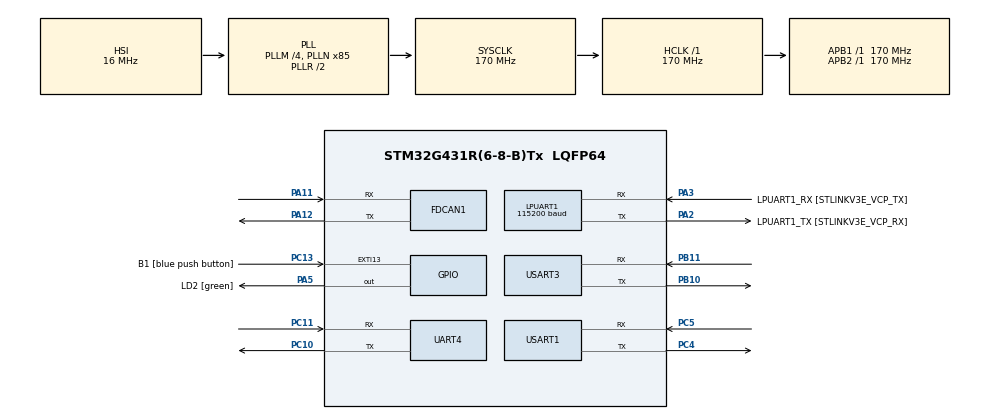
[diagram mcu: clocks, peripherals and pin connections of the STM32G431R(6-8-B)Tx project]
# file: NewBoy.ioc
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Dma.LPUART1_RX.0.Direction=DMA_PERIPH_TO_MEMORY
Dma.LPUART1_RX.0.EventEnable=DISABLE
Dma.LPUART1_RX.0.Instance=DMA1_Channel1
Dma.LPUART1_RX.0.MemDataAlignment=DMA_MDATAALIGN_BYTE
Dma.LPUART1_RX.0.MemInc=DMA_MINC_ENABLE
Dma.LPUART1_RX.0.Mode=DMA_NORMAL
Dma.LPUART1_RX.0.PeriphDataAlignment=DMA_PDATAALIGN_BYTE
Dma.LPUART1_RX.0.PeriphInc=DMA_PINC_DISABLE
Dma.LPUART1_RX.0.Polarity=HAL_DMAMUX_REQ_GEN_RISING
Dma.LPUART1_RX.0.Priority=DMA_PRIORITY_LOW
Dma.LPUART1_RX.0.RequestNumber=1
Dma.LPUART1_RX.0.SignalID=NONE
Dma.LPUART1_RX.0.SyncEnable=DISABLE
Dma.LPUART1_RX.0.SyncPolarity=HAL_DMAMUX_SYNC_NO_EVENT
Dma.LPUART1_RX.0.SyncRequestNumber=1
Dma.LPUART1_RX.0.SyncSignalID=NONE
Dma.Request0=LPUART1_RX
Dma.Request1=USART1_RX
Dma.Request2=USART3_RX
Dma.Request3=UART4_RX
Dma.UART4_RX.3.Direction=DMA_PERIPH_TO_MEMORY
Dma.UART4_RX.3.EventEnable=DISABLE
Dma.UART4_RX.3.Instance=DMA1_Channel4
Dma.UART4_RX.3.MemDataAlignment=DMA_MDATAALIGN_BYTE
Dma.UART4_RX.3.MemInc=DMA_MINC_ENABLE
Dma.UART4_RX.3.Mode=DMA_NORMAL
Dma.UART4_RX.3.PeriphDataAlignment=DMA_PDATAALIGN_BYTE
Dma.UART4_RX.3.PeriphInc=DMA_PINC_DISABLE
Dma.UART4_RX.3.Polarity=HAL_DMAMUX_REQ_GEN_RISING
Dma.UART4_RX.3.Priority=DMA_PRIORITY_LOW
Dma.UART4_RX.3.RequestNumber=1
Dma.UART4_RX.3.SignalID=NONE
Dma.UART4_RX.3.SyncEnable=DISABLE
Dma.UART4_RX.3.SyncPolarity=HAL_DMAMUX_SYNC_NO_EVENT
Dma.UART4_RX.3.SyncRequestNumber=1
Dma.UART4_RX.3.SyncSignalID=NONE
Dma.USART1_RX.1.Direction=DMA_PERIPH_TO_MEMORY
Dma.USART1_RX.1.EventEnable=DISABLE
Dma.USART1_RX.1.Instance=DMA1_Channel2
Dma.USART1_RX.1.MemDataAlignment=DMA_MDATAALIGN_BYTE
Dma.USART1_RX.1.MemInc=DMA_MINC_ENABLE
Dma.USART1_RX.1.Mode=DMA_NORMAL
Dma.USART1_RX.1.PeriphDataAlignment=DMA_PDATAALIGN_BYTE
Dma.USART1_RX.1.PeriphInc=DMA_PINC_DISABLE
Dma.USART1_RX.1.Polarity=HAL_DMAMUX_REQ_GEN_RISING
Dma.USART1_RX.1.Priority=DMA_PRIORITY_LOW
Dma.USART1_RX.1.RequestNumber=1
Dma.USART1_RX.1.SignalID=NONE
Dma.USART1_RX.1.SyncEnable=DISABLE
Dma.USART1_RX.1.SyncPolarity=HAL_DMAMUX_SYNC_NO_EVENT
Dma.USART1_RX.1.SyncRequestNumber=1
Dma.USART1_RX.1.SyncSignalID=NONE
Dma.USART3_RX.2.Direction=DMA_PERIPH_TO_MEMORY
Dma.USART3_RX.2.EventEnable=DISABLE
Dma.USART3_RX.2.Instance=DMA1_Channel3
Dma.USART3_RX.2.MemDataAlignment=DMA_MDATAALIGN_BYTE
Dma.USART3_RX.2.MemInc=DMA_MINC_ENABLE
Dma.USART3_RX.2.Mode=DMA_NORMAL
Dma.USART3_RX.2.PeriphDataAlignment=DMA_PDATAALIGN_BYTE
Dma.USART3_RX.2.PeriphInc=DMA_PINC_DISABLE
Dma.USART3_RX.2.Polarity=HAL_DMAMUX_REQ_GEN_RISING
Dma.USART3_RX.2.Priority=DMA_PRIORITY_LOW
Dma.USART3_RX.2.RequestNumber=1
Dma.USART3_RX.2.SignalID=NONE
Dma.USART3_RX.2.SyncEnable=DISABLE
Dma.USART3_RX.2.SyncPolarity=HAL_DMAMUX_SYNC_NO_EVENT
Dma.USART3_RX.2.SyncRequestNumber=1
Dma.USART3_RX.2.SyncSignalID=NONE
FREERTOS.Tasks01=defaultTask,24,128,StartDefaultTask,Default,NULL,Dynamic,NULL,NULL
LPUART1.BaudRate=115200
Mcu.Family=STM32G4
Mcu.Name=STM32G431R(6-8-B)Tx
Mcu.Package=LQFP64
NVIC.DMA1_Channel1_IRQn=true\:0\:0\:false\:false\:true\:true\:false\:true
NVIC.DMA1_Channel2_IRQn=true\:0\:0\:false\:false\:true\:true\:false\:true
NVIC.DMA1_Channel3_IRQn=true\:0\:0\:false\:false\:true\:true\:false\:true
NVIC.DMA1_Channel4_IRQn=true\:0\:0\:false\:false\:true\:true\:false\:true
NVIC.LPUART1_IRQn=true\:0\:0\:false\:false\:true\:true\:true\:true
NVIC.PriorityGroup=NVIC_PRIORITYGROUP_4
NVIC.TIM1_UP_TIM16_IRQn=true\:0\:0\:false\:false\:true\:false\:false\:true
NVIC.TimeBase=TIM1_UP_TIM16_IRQn
NVIC.TimeBaseIP=TIM1
NVIC.UART4_IRQn=true\:0\:0\:false\:false\:true\:true\:true\:true
NVIC.USART1_IRQn=true\:0\:0\:false\:false\:true\:true\:true\:true
NVIC.USART3_IRQn=true\:0\:0\:false\:false\:true\:true\:true\:true
PA11.Mode=FDCANMaster
PA11.Signal=FDCAN1_RX
PA12.Mode=FDCANMaster
PA12.Signal=FDCAN1_TX
PA13.GPIO_Label=T_SWDIO
PA13.Mode=Serial_Wire
PA13.Signal=SYS_JTMS-SWDIO
PA14.GPIO_Label=T_SWCLK
PA14.Mode=Serial_Wire
PA14.Signal=SYS_JTCK-SWCLK
PA2.GPIO_Label=LPUART1_TX [STLINKV3E_VCP_RX]
PA2.Mode=Asynchronous
PA2.Signal=LPUART1_TX
PA3.GPIO_Label=LPUART1_RX [STLINKV3E_VCP_TX]
PA3.GPIO_PuPd=GPIO_PULLUP
PA3.Mode=Asynchronous
PA3.Signal=LPUART1_RX
PA5.GPIO_Label=LD2 [green]
PA5.Signal=GPIO_Output
PB10.Mode=Asynchronous
PB10.Signal=USART3_TX
PB11.GPIO_PuPd=GPIO_PULLUP
PB11.Mode=Asynchronous
PB11.Signal=USART3_RX
PB3.GPIO_Label=T_SWO
PB3.Signal=SYS_JTDO-SWO
PC10.Mode=Asynchronous
PC10.Signal=UART4_TX
PC11.GPIO_PuPd=GPIO_PULLUP
PC11.Mode=Asynchronous
PC11.Signal=UART4_RX
PC13.GPIO_Label=B1 [blue push button]
PC13.Signal=GPXTI13
PC14-OSC32_IN.Mode=LSE-External-Oscillator
PC14-OSC32_IN.Signal=RCC_OSC32_IN
PC15-OSC32_OUT.Mode=LSE-External-Oscillator
PC15-OSC32_OUT.Signal=RCC_OSC32_OUT
PC4.Mode=Asynchronous
PC4.Signal=USART1_TX
PC5.GPIO_PuPd=GPIO_PULLUP
PC5.Mode=Asynchronous
PC5.Signal=USART1_RX
PF0-OSC_IN.Mode=HSE-External-Oscillator
PF0-OSC_IN.Signal=RCC_OSC_IN
PF1-OSC_OUT.Mode=HSE-External-Oscillator
PF1-OSC_OUT.Signal=RCC_OSC_OUT
ProjectManager.HeapSize=0x200
ProjectManager.StackSize=0x400
ProjectManager.TargetToolchain=STM32CubeIDE
RCC.ADC12Freq_Value=170000000
RCC.AHBFreq_Value=170000000
RCC.APB1Freq_Value=170000000
RCC.APB1TimFreq_Value=170000000
RCC.APB2Freq_Value=170000000
RCC.APB2TimFreq_Value=170000000
RCC.CortexFreq_Value=170000000
RCC.EXTERNAL_CLOCK_VALUE=12288000
RCC.HCLKFreq_Value=170000000
RCC.HSE_VALUE=24000000
RCC.HSI48_VALUE=48000000
RCC.HSI_VALUE=16000000
RCC.PLLM=RCC_PLLM_DIV4
RCC.PLLN=85
RCC.RTCClockSelection=RCC_RTCCLKSOURCE_LSE
RCC.SYSCLKFreq_VALUE=170000000
RCC.SYSCLKSource=RCC_SYSCLKSOURCE_PLLCLK
RCC.USBFreq_Value=170000000
RCC.VCOOutputFreq_Value=340000000
USART1.VirtualMode-Asynchronous=VM_ASYNC
USART3.VirtualMode-Asynchronous=VM_ASYNC
VP_FREERTOS_VS_CMSIS_V2.Mode=CMSIS_V2
VP_SYS_VS_DBSignals.Mode=DisableDeadBatterySignals
VP_SYS_VS_tim1.Mode=TIM1
board=NUCLEO-G431RB

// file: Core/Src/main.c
/* USER CODE BEGIN Header */
/**
  ******************************************************************************
  * @file           : main.c
  * @brief          : Main program body
  ******************************************************************************
  * @attention
  *
  * <h2><center>&copy; Copyright (c) 2020 STMicroelectronics.
  * All rights reserved.</center></h2>
  *
  * This software component is licensed by ST under BSD 3-Clause license,
  * the "License"; You may not use this file except in compliance with the
  * License. You may obtain a copy of the License at:
  *                        opensource.org/licenses/BSD-3-Clause
  *
  ******************************************************************************
  */
/* USER CODE END Header */
#include "main.h"
#include "cmsis_os.h"
#include "dma.h"
#include "fdcan.h"
#include "usart.h"
#include "gpio.h"

void SystemClock_Config(void);
void MX_FREERTOS_Init(void);
/* USER CODE BEGIN PFP */
void netmodule_thread(void *argument);
/* USER CODE END PFP */

int main(void)
{

  /* MCU Configuration--------------------------------------------------------*/

  /* Reset of all peripherals, Initializes the Flash interface and the Systick. */
  HAL_Init();

  /* Configure the system clock */
  SystemClock_Config();

  /* Initialize all configured peripherals */
  MX_GPIO_Init();
  MX_DMA_Init();
  MX_LPUART1_UART_Init();
  MX_FDCAN1_Init();
  MX_UART4_Init();
  MX_USART1_UART_Init();
  MX_USART3_UART_Init();

  /* Init scheduler */
  osKernelInitialize();  /* Call init function for freertos objects (in freertos.c) */
  MX_FREERTOS_Init();
  /* Start scheduler */
  osKernelStart();

  /* We should never get here as control is now taken by the scheduler */
  /* Infinite loop */
  while (1)
  {

  }
}

void SystemClock_Config(void)
{
  RCC_OscInitTypeDef RCC_OscInitStruct = {0};
  RCC_ClkInitTypeDef RCC_ClkInitStruct = {0};
  RCC_PeriphCLKInitTypeDef PeriphClkInit = {0};

  /** Configure the main internal regulator output voltage
  */
  HAL_PWREx_ControlVoltageScaling(PWR_REGULATOR_VOLTAGE_SCALE1_BOOST);
  /** Initializes the RCC Oscillators according to the specified parameters
  * in the RCC_OscInitTypeDef structure.
  */
  RCC_OscInitStruct.OscillatorType = RCC_OSCILLATORTYPE_HSI;
  RCC_OscInitStruct.HSIState = RCC_HSI_ON;
  RCC_OscInitStruct.HSICalibrationValue = RCC_HSICALIBRATION_DEFAULT;
  RCC_OscInitStruct.PLL.PLLState = RCC_PLL_ON;
  RCC_OscInitStruct.PLL.PLLSource = RCC_PLLSOURCE_HSI;
  RCC_OscInitStruct.PLL.PLLM = RCC_PLLM_DIV4;
  RCC_OscInitStruct.PLL.PLLN = 85;
  RCC_OscInitStruct.PLL.PLLP = RCC_PLLP_DIV2;
  RCC_OscInitStruct.PLL.PLLQ = RCC_PLLQ_DIV2;
  RCC_OscInitStruct.PLL.PLLR = RCC_PLLR_DIV2;
  if (HAL_RCC_OscConfig(&RCC_OscInitStruct) != HAL_OK)
  {
    Error_Handler();
  }
  /** Initializes the CPU, AHB and APB buses clocks
  */
  RCC_ClkInitStruct.ClockType = RCC_CLOCKTYPE_HCLK|RCC_CLOCKTYPE_SYSCLK
                              |RCC_CLOCKTYPE_PCLK1|RCC_CLOCKTYPE_PCLK2;
  RCC_ClkInitStruct.SYSCLKSource = RCC_SYSCLKSOURCE_PLLCLK;
  RCC_ClkInitStruct.AHBCLKDivider = RCC_SYSCLK_DIV1;
  RCC_ClkInitStruct.APB1CLKDivider = RCC_HCLK_DIV1;
  RCC_ClkInitStruct.APB2CLKDivider = RCC_HCLK_DIV1;

  if (HAL_RCC_ClockConfig(&RCC_ClkInitStruct, FLASH_LATENCY_4) != HAL_OK)
  {
    Error_Handler();
  }
  /** Initializes the peripherals clocks
  */
  PeriphClkInit.PeriphClockSelection = RCC_PERIPHCLK_USART1|RCC_PERIPHCLK_USART3
                              |RCC_PERIPHCLK_UART4|RCC_PERIPHCLK_LPUART1
                              |RCC_PERIPHCLK_FDCAN;
  PeriphClkInit.Usart1ClockSelection = RCC_USART1CLKSOURCE_PCLK2;
  PeriphClkInit.Usart3ClockSelection = RCC_USART3CLKSOURCE_PCLK1;
  PeriphClkInit.Uart4ClockSelection = RCC_UART4CLKSOURCE_PCLK1;
  PeriphClkInit.Lpuart1ClockSelection = RCC_LPUART1CLKSOURCE_PCLK1;
  PeriphClkInit.FdcanClockSelection = RCC_FDCANCLKSOURCE_PCLK1;
  if (HAL_RCCEx_PeriphCLKConfig(&PeriphClkInit) != HAL_OK)
  {
    Error_Handler();
  }
}

/* USER CODE BEGIN 4 */
void netmodule_thread(void *argument)
{
}
/* USER CODE END 4 */

void HAL_TIM_PeriodElapsedCallback(TIM_HandleTypeDef *htim)
{
  if (htim->Instance == TIM1) {
    HAL_IncTick();
  }
}

void Error_Handler(void)
{
}

/************************ (C) COPYRIGHT STMicroelectronics *****END OF FILE****/

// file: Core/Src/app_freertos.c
/* USER CODE BEGIN Header */
/**
  ******************************************************************************
  * File Name          : app_freertos.c
  * Description        : Code for freertos applications
  ******************************************************************************
  * @attention
  *
  * <h2><center>&copy; Copyright (c) 2020 STMicroelectronics.
  * All rights reserved.</center></h2>
  *
  * This software component is licensed by ST under Ultimate Liberty license
  * SLA0044, the "License"; You may not use this file except in compliance with
  * the License. You may obtain a copy of the License at:
  *                             www.st.com/SLA0044
  *
  ******************************************************************************
  */
/* USER CODE END Header */

#include "FreeRTOS.h"
#include "task.h"
#include "main.h"
#include "cmsis_os.h"

/* USER CODE BEGIN Includes */
#include "usart.h"
/* USER CODE END Includes */

/* Definitions for defaultTask */
osThreadId_t defaultTaskHandle;
const osThreadAttr_t defaultTask_attributes = {
  .name = "defaultTask",
  .priority = (osPriority_t) osPriorityNormal,
  .stack_size = 128 * 4
};

void StartDefaultTask(void *argument);

void MX_FREERTOS_Init(void); /* (MISRA C 2004 rule 8.1) */

void MX_FREERTOS_Init(void) {

  /* Create the thread(s) */
  /* creation of defaultTask */
  defaultTaskHandle = osThreadNew(StartDefaultTask, NULL, &defaultTask_attributes);

}

void StartDefaultTask(void *argument)
{
  /* USER CODE BEGIN StartDefaultTask */
  /* Infinite loop */
  while (1)
  {
	HAL_Delay(1000);
	printf("haha\r\n");
  }

  /* USER CODE END StartDefaultTask */
}

/************************ (C) COPYRIGHT STMicroelectronics *****END OF FILE****/
